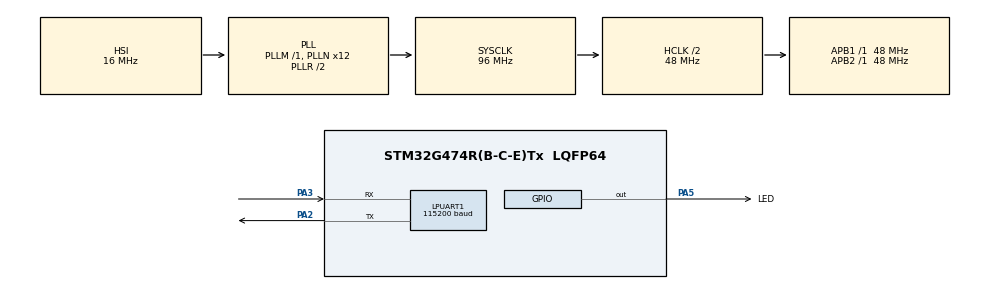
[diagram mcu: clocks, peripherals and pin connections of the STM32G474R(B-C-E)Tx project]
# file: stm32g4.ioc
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FREERTOS.Tasks01=defaultTask,24,128,StartDefaultTask,Default,NULL,Dynamic,NULL,NULL
FREERTOS.configUSE_NEWLIB_REENTRANT=1
LPUART1.BaudRate=115200
Mcu.Family=STM32G4
Mcu.Name=STM32G474R(B-C-E)Tx
Mcu.Package=LQFP64
NVIC.LPUART1_IRQn=true\:5\:0\:false\:false\:true\:true\:true\:true\:true
NVIC.PriorityGroup=NVIC_PRIORITYGROUP_4
NVIC.TIM6_DAC_IRQn=true\:15\:0\:false\:false\:true\:false\:false\:true\:true
NVIC.TimeBase=TIM6_DAC_IRQn
NVIC.TimeBaseIP=TIM6
PA2.Mode=Asynchronous
PA2.Signal=LPUART1_TX
PA3.Mode=Asynchronous
PA3.Signal=LPUART1_RX
PA5.GPIO_Label=LED
PA5.Signal=GPIO_Output
ProjectManager.HeapSize=0x200
ProjectManager.StackSize=0x400
ProjectManager.TargetToolchain=STM32CubeIDE
RCC.ADC12Freq_Value=96000000
RCC.ADC345Freq_Value=96000000
RCC.AHBCLKDivider=RCC_SYSCLK_DIV2
RCC.AHBFreq_Value=48000000
RCC.APB1Freq_Value=48000000
RCC.APB1TimFreq_Value=48000000
RCC.APB2Freq_Value=48000000
RCC.APB2TimFreq_Value=48000000
RCC.CortexFreq_Value=48000000
RCC.EXTERNAL_CLOCK_VALUE=12288000
RCC.HCLKFreq_Value=48000000
RCC.HSE_VALUE=8000000
RCC.HSI48_VALUE=48000000
RCC.HSI_VALUE=16000000
RCC.LSE_VALUE=32768
RCC.PLLN=12
RCC.SYSCLKFreq_VALUE=96000000
RCC.SYSCLKSource=RCC_SYSCLKSOURCE_PLLCLK
RCC.USBFreq_Value=96000000
RCC.VCOOutputFreq_Value=192000000
VP_FREERTOS_VS_CMSIS_V2.Mode=CMSIS_V2
VP_SYS_VS_DBSignals.Mode=DisableDeadBatterySignals
VP_SYS_VS_tim6.Mode=TIM6
board=custom

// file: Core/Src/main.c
/* USER CODE BEGIN Header */
/**
  ******************************************************************************
  * @file           : main.c
  * @brief          : Main program body
  ******************************************************************************
  * @attention
  *
  * Copyright (c) 2024 STMicroelectronics.
  * All rights reserved.
  *
  * This software is licensed under terms that can be found in the LICENSE file
  * in the root directory of this software component.
  * If no LICENSE file comes with this software, it is provided AS-IS.
  *
  ******************************************************************************
  */
/* USER CODE END Header */
#include "main.h"
#include "cmsis_os.h"

/* USER CODE BEGIN Includes */
#include "stdio.h"
/* USER CODE END Includes */

UART_HandleTypeDef hlpuart1;

/* Definitions for defaultTask */
osThreadId_t defaultTaskHandle;
const osThreadAttr_t defaultTask_attributes = {
  .name = "defaultTask",
  .priority = (osPriority_t) osPriorityNormal,
  .stack_size = 128 * 4
};

void SystemClock_Config(void);
static void MX_GPIO_Init(void);
static void MX_LPUART1_UART_Init(void);
void StartDefaultTask(void *argument);

/* USER CODE BEGIN PFP */
#ifdef __GNUC__
/* With GCC, small printf (option LD Linker->Libraries->Small printf
   set to 'Yes') calls __io_putchar() */
#define PUTCHAR_PROTOTYPE int __io_putchar(int ch)
#else
#define PUTCHAR_PROTOTYPE int fputc(int ch, FILE *f)
#endif /* __GNUC__ */
/* USER CODE END PFP */

int main(void)
{

  /* MCU Configuration--------------------------------------------------------*/

  /* Reset of all peripherals, Initializes the Flash interface and the Systick. */
  HAL_Init();

  /* Configure the system clock */
  SystemClock_Config();

  /* Initialize all configured peripherals */
  MX_GPIO_Init();
  MX_LPUART1_UART_Init();

  /* Init scheduler */
  osKernelInitialize();

  /* Create the thread(s) */
  /* creation of defaultTask */
  defaultTaskHandle = osThreadNew(StartDefaultTask, NULL, &defaultTask_attributes);

  /* Start scheduler */
  osKernelStart();

  /* We should never get here as control is now taken by the scheduler */

  /* Infinite loop */
  while (1)
  {
  }
}

void SystemClock_Config(void)
{
  RCC_OscInitTypeDef RCC_OscInitStruct = {0};
  RCC_ClkInitTypeDef RCC_ClkInitStruct = {0};

  /** Configure the main internal regulator output voltage
  */
  HAL_PWREx_ControlVoltageScaling(PWR_REGULATOR_VOLTAGE_SCALE1);

  /** Initializes the RCC Oscillators according to the specified parameters
  * in the RCC_OscInitTypeDef structure.
  */
  RCC_OscInitStruct.OscillatorType = RCC_OSCILLATORTYPE_HSI;
  RCC_OscInitStruct.HSIState = RCC_HSI_ON;
  RCC_OscInitStruct.HSICalibrationValue = RCC_HSICALIBRATION_DEFAULT;
  RCC_OscInitStruct.PLL.PLLState = RCC_PLL_ON;
  RCC_OscInitStruct.PLL.PLLSource = RCC_PLLSOURCE_HSI;
  RCC_OscInitStruct.PLL.PLLM = RCC_PLLM_DIV1;
  RCC_OscInitStruct.PLL.PLLN = 12;
  RCC_OscInitStruct.PLL.PLLP = RCC_PLLP_DIV2;
  RCC_OscInitStruct.PLL.PLLQ = RCC_PLLQ_DIV2;
  RCC_OscInitStruct.PLL.PLLR = RCC_PLLR_DIV2;
  if (HAL_RCC_OscConfig(&RCC_OscInitStruct) != HAL_OK)
  {
    Error_Handler();
  }

  /** Initializes the CPU, AHB and APB buses clocks
  */
  RCC_ClkInitStruct.ClockType = RCC_CLOCKTYPE_HCLK|RCC_CLOCKTYPE_SYSCLK
                              |RCC_CLOCKTYPE_PCLK1|RCC_CLOCKTYPE_PCLK2;
  RCC_ClkInitStruct.SYSCLKSource = RCC_SYSCLKSOURCE_PLLCLK;
  RCC_ClkInitStruct.AHBCLKDivider = RCC_SYSCLK_DIV2;
  RCC_ClkInitStruct.APB1CLKDivider = RCC_HCLK_DIV1;
  RCC_ClkInitStruct.APB2CLKDivider = RCC_HCLK_DIV1;

  if (HAL_RCC_ClockConfig(&RCC_ClkInitStruct, FLASH_LATENCY_1) != HAL_OK)
  {
    Error_Handler();
  }
}

static void MX_LPUART1_UART_Init(void)
{

  hlpuart1.Instance = LPUART1;
  hlpuart1.Init.BaudRate = 115200;
  hlpuart1.Init.WordLength = UART_WORDLENGTH_8B;
  hlpuart1.Init.StopBits = UART_STOPBITS_1;
  hlpuart1.Init.Parity = UART_PARITY_NONE;
  hlpuart1.Init.Mode = UART_MODE_TX_RX;
  hlpuart1.Init.HwFlowCtl = UART_HWCONTROL_NONE;
  hlpuart1.Init.OneBitSampling = UART_ONE_BIT_SAMPLE_DISABLE;
  hlpuart1.Init.ClockPrescaler = UART_PRESCALER_DIV1;
  hlpuart1.AdvancedInit.AdvFeatureInit = UART_ADVFEATURE_NO_INIT;
  if (HAL_UART_Init(&hlpuart1) != HAL_OK)
  {
    Error_Handler();
  }
  if (HAL_UARTEx_SetTxFifoThreshold(&hlpuart1, UART_TXFIFO_THRESHOLD_1_8) != HAL_OK)
  {
    Error_Handler();
  }
  if (HAL_UARTEx_SetRxFifoThreshold(&hlpuart1, UART_RXFIFO_THRESHOLD_1_8) != HAL_OK)
  {
    Error_Handler();
  }
  if (HAL_UARTEx_DisableFifoMode(&hlpuart1) != HAL_OK)
  {
    Error_Handler();
  }

}

static void MX_GPIO_Init(void)
{
  GPIO_InitTypeDef GPIO_InitStruct = {0};

  /* GPIO Ports Clock Enable */
  __HAL_RCC_GPIOA_CLK_ENABLE();

  /*Configure GPIO pin Output Level */
  HAL_GPIO_WritePin(LED_GPIO_Port, LED_Pin, GPIO_PIN_RESET);

  /*Configure GPIO pin : LED_Pin */
  GPIO_InitStruct.Pin = LED_Pin;
  GPIO_InitStruct.Mode = GPIO_MODE_OUTPUT_PP;
  GPIO_InitStruct.Pull = GPIO_NOPULL;
  GPIO_InitStruct.Speed = GPIO_SPEED_FREQ_LOW;
  HAL_GPIO_Init(LED_GPIO_Port, &GPIO_InitStruct);

}

/* USER CODE BEGIN 4 */
/**
  * @brief  Retargets the C library printf function to the USART.
  * @param  None
  * @retval None
  */
PUTCHAR_PROTOTYPE
{
  /* Place your implementation of fputc here */
  /* e.g. write a character to the LPUART1 and Loop until the end of transmission */
  HAL_UART_Transmit(&hlpuart1, (uint8_t *)&ch, 1, 0xFFFF);

  return ch;
}
/* USER CODE END 4 */

void StartDefaultTask(void *argument)
{
  /* USER CODE BEGIN 5 */
  int i = 0;
  /* Infinite loop */
  //printf("hash %s", GIT_HASH);

  for(;;)
  {
    osDelay(1000);
    HAL_GPIO_TogglePin(LED_GPIO_Port,LED_Pin);
    printf("test %d : %d.%d.%d \n",i++,VERSION_MAJOR,VERSION_MINOR,VERSION_BUGFIX);
    printf("git hash %s \n",VERSION_SHORT_GIT_HASH);
  }
  /* USER CODE END 5 */
}

void HAL_TIM_PeriodElapsedCallback(TIM_HandleTypeDef *htim)
{
  if (htim->Instance == TIM6) {
    HAL_IncTick();
  }
}

void Error_Handler(void)
{
  __disable_irq();
  while (1)
  {
  }
}
